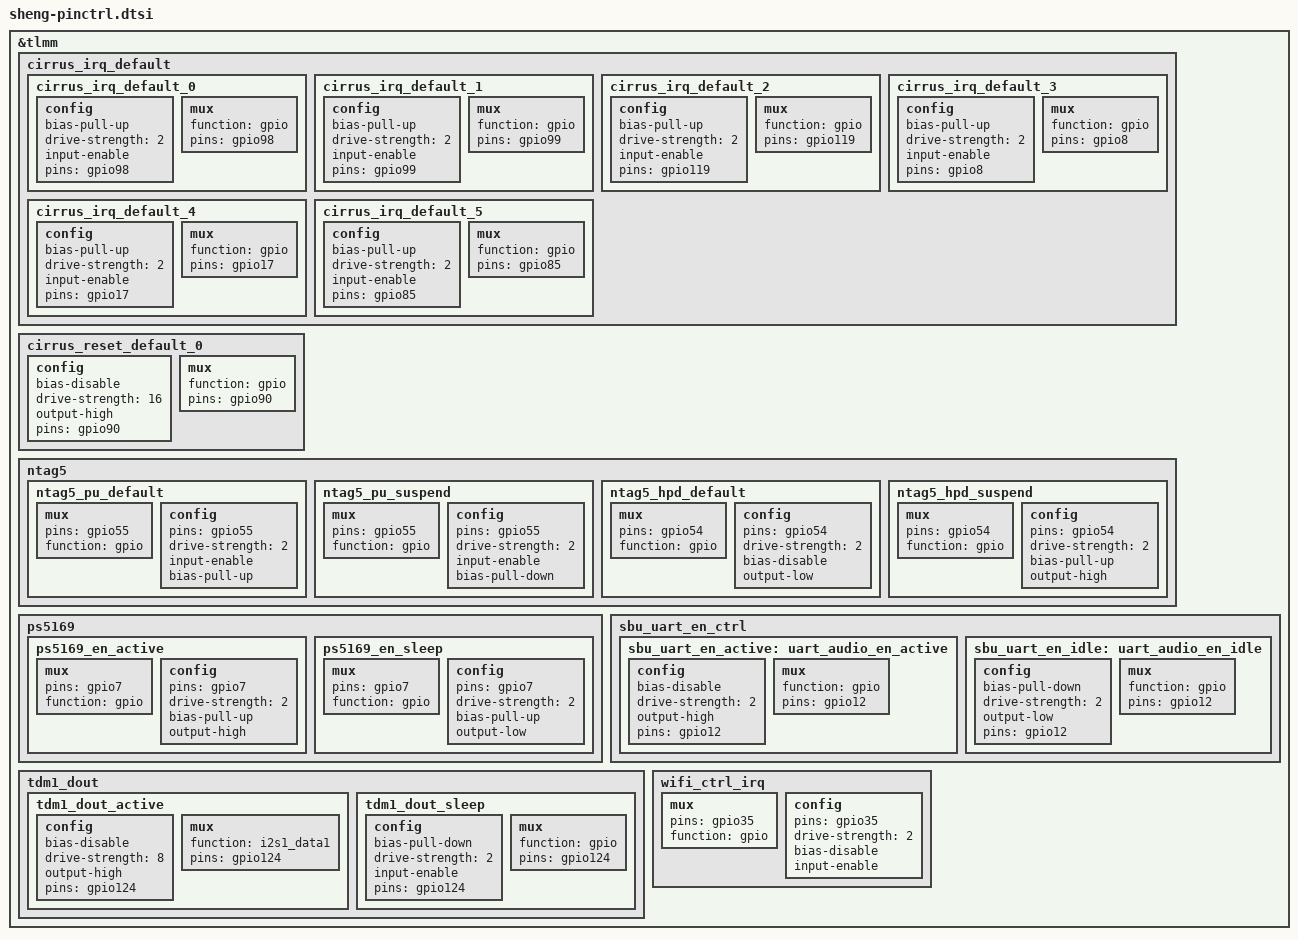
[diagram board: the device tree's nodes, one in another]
/*for sheng pinctrl */
&tlmm {
	cirrus_irq_default {
		cirrus_irq_default_0: cirrus_irq_default_0 {
			config {
				bias-pull-up;
				drive-strength = <2>; /* 2 MA */
				input-enable;
				pins = "gpio98";
			};

			mux {
				function = "gpio";
				pins = "gpio98";
			};
		};

		cirrus_irq_default_1: cirrus_irq_default_1 {
			config {
				bias-pull-up;
				drive-strength = <2>; /* 2 MA */
				input-enable;
				pins = "gpio99";
			};

			mux {
				function = "gpio";
				pins = "gpio99";
			};
		};

		cirrus_irq_default_2: cirrus_irq_default_2 {
			config {
				bias-pull-up;
				drive-strength = <2>; /* 2 MA */
				input-enable;
				pins = "gpio119";
			};

			mux {
				function = "gpio";
				pins = "gpio119";
			};
		};

		cirrus_irq_default_3: cirrus_irq_default_3 {
			config {
				bias-pull-up;
				drive-strength = <2>; /* 2 MA */
				input-enable;
				pins = "gpio8";
			};

			mux {
				function = "gpio";
				pins = "gpio8";
			};
		};

		cirrus_irq_default_4: cirrus_irq_default_4 {
			config {
				bias-pull-up;
				drive-strength = <2>; /* 2 MA */
				input-enable;
				pins = "gpio17";
			};

			mux {
				function = "gpio";
				pins = "gpio17";
			};
		};

		cirrus_irq_default_5: cirrus_irq_default_5 {
			config {
				bias-pull-up;
				drive-strength = <2>; /* 2 MA */
				input-enable;
				pins = "gpio85";
			};

			mux {
				function = "gpio";
				pins = "gpio85";
			};
		};
	};

	cirrus_reset_default_0: cirrus_reset_default_0 {
		config {
			bias-disable;
			drive-strength = <16>; /* 16 MA */
			output-high;
			pins = "gpio90";
		};
		mux {
			function = "gpio";
			pins = "gpio90";
		};
	};

	ntag5 {
			ntag5_pu_default: ntag5_pu_default {
					mux {
						pins = "gpio55";
						function = "gpio";
					};

					config {
						pins = "gpio55";
						drive-strength = <2>; /* 2 MA */
						input-enable;
						/* 拉高方式恢复 */
						bias-pull-up;
					};
			};

			ntag5_pu_suspend: ntag5_pu_suspend {
					mux {
						pins = "gpio55";
						function = "gpio";
					};

					config {
						pins = "gpio55";
						drive-strength = <2>; /* 2 MA */
						input-enable;
						/* 拉低方式触发 */
						bias-pull-down;
					};
			};

			ntag5_hpd_default: ntag5_hpd_default {
					mux {
						pins = "gpio54";
						function = "gpio";
					};

					config {
						pins = "gpio54";
						drive-strength = <2>; /* 2 MA */
						// 默认态 bias-disable是悬空
						bias-disable;
						output-low;
					};
			};

			ntag5_hpd_suspend: ntag5_hpd_suspend {
					mux {
						pins = "gpio54";
						function = "gpio";
					};

					config {
						pins = "gpio54";
						drive-strength = <2>; /* 2 MA */
						/* 拉高方式触发 */
						bias-pull-up;
						output-high;
					};
			};
	};

	ps5169 {
		ps5169_en_active: ps5169_en_active {
			mux {
				pins = "gpio7";
				function = "gpio";
			};
			config {
				pins = "gpio7";
				drive-strength = <2>; /* 2 MA */
				bias-pull-up;
				output-high;
			};
		};
		ps5169_en_sleep: ps5169_en_sleep {
			mux {
				pins = "gpio7";
				function = "gpio";
			};
			config {
				pins = "gpio7";
				drive-strength = <2>; /* 2 MA */
				bias-pull-up;
				output-low;
			};
		};
	};

	sbu_uart_en_ctrl {
		sbu_uart_en_active: uart_audio_en_active {
			config {
				bias-disable;
				drive-strength = <2>; /* 2 MA */
				output-high;
				pins = "gpio12";
			};

			mux {
				function = "gpio";
				pins = "gpio12";
			};
		};

		sbu_uart_en_idle: uart_audio_en_idle {
			config {
				bias-pull-down;
				drive-strength = <2>; /* 2 MA */
				output-low;
				pins = "gpio12";
			};

			mux {
				function = "gpio";
				pins = "gpio12";
			};
		};
	};

	tdm1_dout {
		tdm1_dout_active: tdm1_dout_active {
			config {
				bias-disable;
				drive-strength = <8>; /* 8 MA */
				output-high;
				pins = "gpio124";
			};

			mux {
				function = "i2s1_data1";
				pins = "gpio124";
			};
		};

		tdm1_dout_sleep: tdm1_dout_sleep {
			config {
				bias-pull-down;
				drive-strength = <2>; /* 2 MA */
				input-enable;
				pins = "gpio124";
			};

			mux {
				function = "gpio";
				pins = "gpio124";
			};
		};
	};

	wifi_ctrl_irq: wifi_ctrl_irq {
		mux {
			pins = "gpio35";
			function = "gpio";
		};

		config {
			pins = "gpio35";
			drive-strength = <2>;   /* 2 mA */
			bias-disable;
			input-enable;
		};
	};
};
